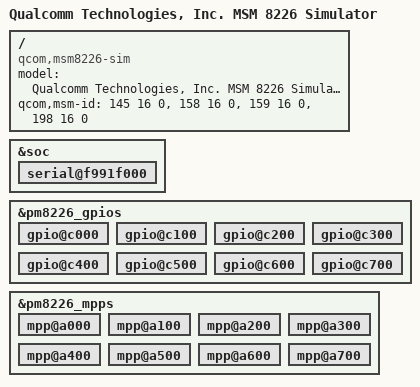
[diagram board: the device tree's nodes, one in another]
/* Copyright (c) 2012-2014, The Linux Foundation. All rights reserved.
 *
 * This program is free software; you can redistribute it and/or modify
 * it under the terms of the GNU General Public License version 2 and
 * only version 2 as published by the Free Software Foundation.
 *
 * This program is distributed in the hope that it will be useful,
 * but WITHOUT ANY WARRANTY; without even the implied warranty of
 * MERCHANTABILITY or FITNESS FOR A PARTICULAR PURPOSE.  See the
 * GNU General Public License for more details.
 */

/dts-v1/;
#include "msm8226.dtsi"
#include "msm8226-memory.dtsi"

/ {
	model = "Qualcomm Technologies, Inc. MSM 8226 Simulator";
	compatible = "qcom,msm8226-sim", "qcom,msm8226", "qcom,sim";
	qcom,msm-id = <145 16 0>,
		      <158 16 0>,
		      <159 16 0>,
		      <198 16 0>;
};

&soc {
	serial@f991f000 {
		status = "ok";
	};
};

&pm8226_gpios {
	gpio@c000 { /* GPIO 1 */
	};

	gpio@c100 { /* GPIO 2 */
	};

	gpio@c200 { /* GPIO 3 */
	};

	gpio@c300 { /* GPIO 4 */
	};

	gpio@c400 { /* GPIO 5 */
	};

	gpio@c500 { /* GPIO 6 */
	};

	gpio@c600 { /* GPIO 7 */
	};

	gpio@c700 { /* GPIO 8 */
	};
};

&pm8226_mpps {
	mpp@a000 { /* MPP 1 */
	};

	mpp@a100 { /* MPP 2 */
	};

	mpp@a200 { /* MPP 3 */
	};

	mpp@a300 { /* MPP 4 */
	};

	mpp@a400 { /* MPP 5 */
	};

	mpp@a500 { /* MPP 6 */
	};

	mpp@a600 { /* MPP 7 */
	};

	mpp@a700 { /* MPP 8 */
	};
};


